# G32R502 register map
Vendor: Geehy Semiconductor Co., Ltd.; Series: G32R5; File version: 1.0
CPU: CM52 r0p1, little endian, MPU, FPU, DSP, VTOR, 4 interrupt priority bits
Registers are 32-bit, read-write, reset 0x0 unless marked. A register's access mark holds for its fields unless they carry their own. Offsets are from the block's base; [hi:lo] are bit positions; {n}, {i} and the like mark numbered series; 'fields as' and 'values as' point back to an identical list.

## AS — Analog Subsystem (AS)
Base 0x40016C00
0xBC CONFIGLOCK 16-bit — Lock Register for all the config registers.
  [3] AGPIOCTRL — Locks all AGPIOCTRL Register
0xC0 TSNSCTL 16-bit — Temperature Sensor Control Register
  [0] ENABLE — Temperature Sensor Enable
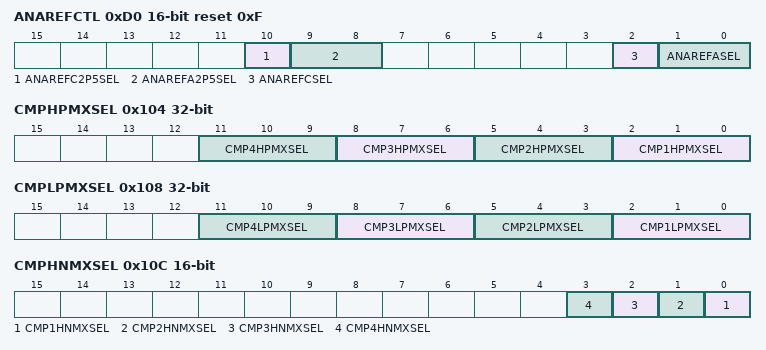
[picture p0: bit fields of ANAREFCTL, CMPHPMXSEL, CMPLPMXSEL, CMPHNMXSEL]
0xD0 ANAREFCTL 16-bit reset 0xF — Analog Reference Control Register
  [10] ANAREFC2P5SEL — Analog reference C 2.5V select
  [9:8] ANAREFA2P5SEL — Analog reference A 2.5V select
  [2] ANAREFCSEL — Analog reference C mode select
  [1:0] ANAREFASEL — Analog reference A mode select
0xE0 VMONCTL 16-bit — Voltage Monitor Control Register
  [8] BORLDIS — BORL disable on VDDIO
0x104 CMPHPMXSEL — COMP_HP select source register
  [3n-1:3n-3] CMP{n}HPMXSEL (n=1..4) — Select source on the COMP{n}_HP input
0x108 CMPLPMXSEL — COMP_LP select source register
  [3n-1:3n-3] CMP{n}LPMXSEL (n=1..4) — Select source on the COMP{n}_LP input
0x10C CMPHNMXSEL 16-bit — COMP_HN select source register
  [n-1] CMP{n}HNMXSEL (n=1..4) — Select source on the COMP{n}_HN input
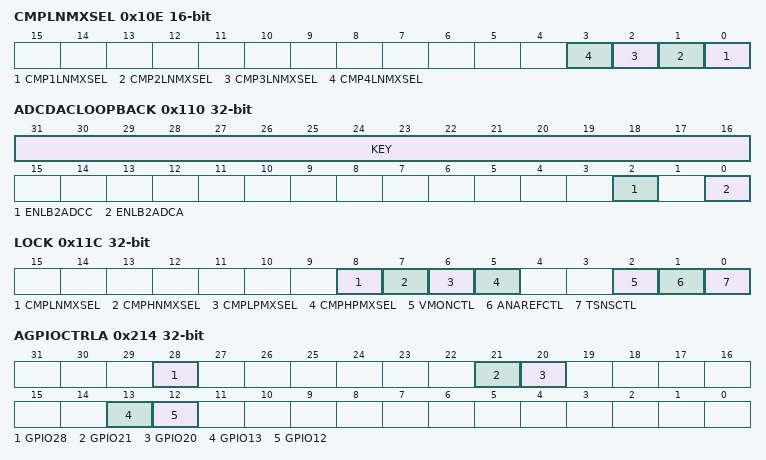
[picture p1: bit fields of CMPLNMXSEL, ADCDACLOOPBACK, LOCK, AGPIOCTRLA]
0x10E CMPLNMXSEL 16-bit — COMP_LN select source register
  [n-1] CMP{n}LNMXSEL (n=1..4) — Select source on the COMP{n}_LN input
0x110 ADCDACLOOPBACK — Enabble loopback from DAC to ADCs
  [31:16] KEY
  [2] ENLB2ADCC — Loopback COMPDACA output to ADCC
  [0] ENLB2ADCA — Loopback COMPDACA output to ADCA
0x11C LOCK
  [8] CMPLNMXSEL — AS_COMPLNMXSEL Register Lock
  [7] CMPHNMXSEL — AS_COMPHNMXSEL Register Lock
  [6] CMPLPMXSEL — AS_COMPLPMXSEL Register Lock
  [5] CMPHPMXSEL — AS_COMPHPMXSEL Register Lock
  [2] VMONCTL — AS_VMCTRL Register Lock
  [1] ANAREFCTL — AREFCTRL Register Lock
  [0] TSNSCTL — AS_TSCTRL Register Lock
0x214 AGPIOCTRLA — AGPIO Control Register A
  [28] GPIO28 — Enable AGPIO function on GPIO28
  [21] GPIO21 — Enable AGPIO function on GPIO21
  [20] GPIO20 — Enable AGPIO function on GPIO20
  [13] GPIO13 — Enable AGPIO function on GPIO13
  [12] GPIO12 — Enable AGPIO function on GPIO12
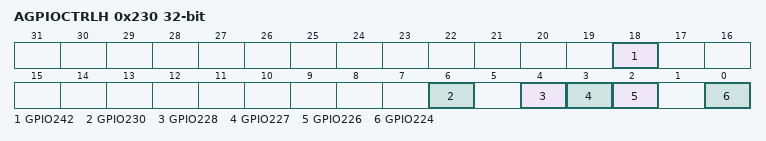
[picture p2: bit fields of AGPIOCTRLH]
0x230 AGPIOCTRLH — AGPIO Control Register H
  [18] GPIO242 — Enable or disable AGPIO function for GPIO242
  [6] GPIO230 — Enable or disable AGPIO function for GPIO230
  [4] GPIO228 — Enable or disable AGPIO function for GPIO228
  [3] GPIO227 — Enable or disable AGPIO function for GPIO227
  [2] GPIO226 — Enable or disable AGPIO function for GPIO226
  [0] GPIO224 — Enable or disable AGPIO function for GPIO224

## CFGSMS — Configurable Static Memory Subsystem(CFGSMS)
Base 0x40012800
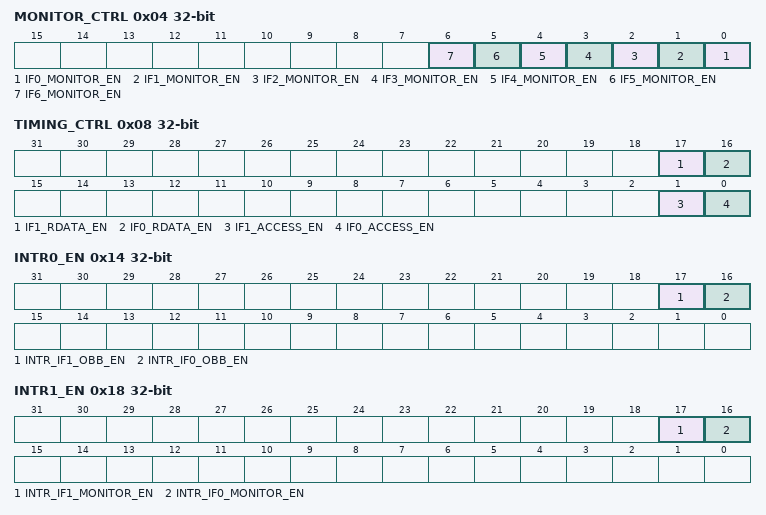
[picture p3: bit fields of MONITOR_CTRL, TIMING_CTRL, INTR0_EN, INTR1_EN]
0x04 MONITOR_CTRL — Monitor Control Register
  [n] IF{n}_MONITOR_EN (n=0..6) — Monitor Enable
0x08 TIMING_CTRL — Timing Control Register
  [17] IF1_RDATA_EN — Read Data Enable
  [16] IF0_RDATA_EN — Read Data Enable
  [1] IF1_ACCESS_EN — Access Enable
  [0] IF0_ACCESS_EN — Access Enable
0x14 INTR0_EN — Interrupt Enable Register 0
  [17] INTR_IF1_OBB_EN — Out of Bank Bounds Interrupt Enable
  [16] INTR_IF0_OBB_EN — Out of Bank Bounds Interrupt Enable
0x18 INTR1_EN — Interrupt Enable Register 1
  [17] INTR_IF1_MONITOR_EN — Monitor Interrupt Enable
  [16] INTR_IF0_MONITOR_EN — Monitor Interrupt Enable
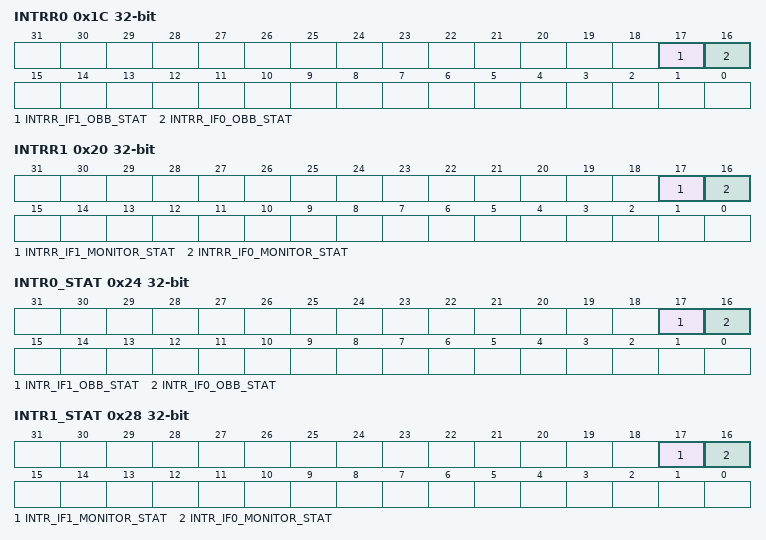
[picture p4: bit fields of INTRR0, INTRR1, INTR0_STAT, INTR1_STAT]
0x1C INTRR0 — Interrupt Raw Register 0
  [17] INTRR_IF1_OBB_STAT — Out of Bank Bounds Interrupt Raw State
  [16] INTRR_IF0_OBB_STAT — Out of Bank Bounds Interrupt Raw State
0x20 INTRR1 — Interrupt Raw Register 1
  [17] INTRR_IF1_MONITOR_STAT — Monitor Interrupt Raw State
  [16] INTRR_IF0_MONITOR_STAT — Monitor Interrupt Raw State
0x24 INTR0_STAT ro — Interrupt Status Register 0
  [17] INTR_IF1_OBB_STAT — Out of Bank Bounds Interrupt State Register
  [16] INTR_IF0_OBB_STAT — Out of Bank Bounds Interrupt State Register
0x28 INTR1_STAT ro — Interrupt Status Register 1
  [17] INTR_IF1_MONITOR_STAT — Monitor Interrupt State Register
  [16] INTR_IF0_MONITOR_STAT — Monitor Interrupt State Register
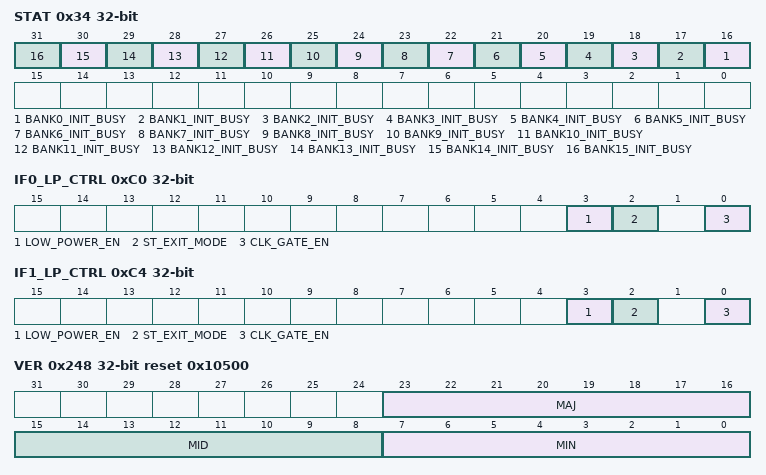
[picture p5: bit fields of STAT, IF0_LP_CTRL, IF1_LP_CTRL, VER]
0x34 STAT ro — Status Register
  [n+16] BANK{n}_INIT_BUSY (n=0..15) — Bank Initiate Busy
0x80 IF0_MONITOR_ADDR — IF0 Monitor Address Register
  [31:0] MONITOR_ADDR — Monitor Address
0x84 IF1_MONITOR_ADDR — IF1 Monitor Address Register
  [31:0] MONITOR_ADDR — Monitor Address
0xC0 IF0_LP_CTRL — IF0 Low Power Control Register
  [3] LOW_POWER_EN — Low Power Enable
  [2] ST_EXIT_MODE — Exit STOP Mode
  [0] CLK_GATE_EN — Clock Gate Enable
0xC4 IF1_LP_CTRL — IF1 Low Power Control Register
  fields as IF0_LP_CTRL
0x100 IF0_LP_CNT0 reset 0x3F — Interface0 Low Power Access Period Register-0
  [7:0] ENTER_LS_CYC — Enter Low-power Mode Cycle
0x104 IF1_LP_CNT0 reset 0x3F — Interface1 Low Power Access Period Register-0
  [7:0] ENTER_LS_CYC — Enter Low-power Mode Cycle
0x140 IF0_LP_CNT1 reset 0x10000 — Interface0 Low Power Access Period Register-1
  [23:16] LS_SETUP_CYC — Setup cycle after Exiting Low Power Mode
0x144 IF1_LP_CNT1 reset 0x10000 — Interface1 Low Power Access Period Register-1
  [23:16] LS_SETUP_CYC — Setup cycle after Exiting Low Power Mode
0x240 IF_IVOL ro — ITCM volume (read-only on G32R502). Updated from static lb_cfg after power-on reset.
  [3:0] ITCM_VOL — ITCM Volume Configuration
0x244 IF_DVOL ro — DTCM volume (read-only on G32R502). Updated from static lb_cfg after power-on reset.
  [3:0] DTCM_VOL — DTCM Volume Configuration
0x248 VER ro reset 0x10500 — Version Register
  [23:16] MAJ — Major revision
  [15:8] MID — Middle revision
  [7:0] MIN — Minor revision
